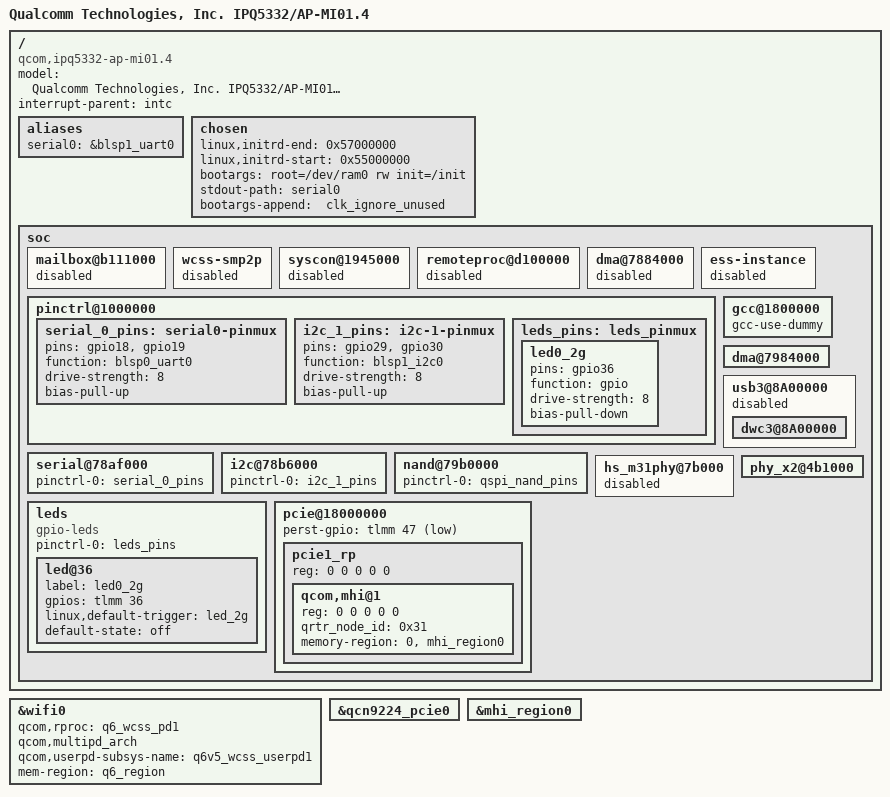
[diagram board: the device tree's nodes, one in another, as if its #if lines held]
// SPDX-License-Identifier: (GPL-2.0+ OR BSD-3-Clause)
/*
 * IPQ5332 AP-MI01.4 board device tree source
 *
 * Copyright (c) 2020-2021 The Linux Foundation. All rights reserved.
 * Copyright (c) 2022 Qualcomm Innovation Center, Inc. All rights reserved.
 */

/dts-v1/;

#include "ipq5332.dtsi"

#ifdef __IPQ_MEM_PROFILE_512_MB__
#include "ipq5332-512MB-memory.dtsi"
#else
#include "ipq5332-default-memory.dtsi"
#endif

/ {
	#address-cells = <0x2>;
	#size-cells = <0x2>;
	model = "Qualcomm Technologies, Inc. IPQ5332/AP-MI01.4";
	compatible = "qcom,ipq5332-ap-mi01.4", "qcom,ipq5332";
	interrupt-parent = <&intc>;

	aliases {
		serial0 = &blsp1_uart0;
	};

	chosen {
		linux,initrd-end = <0x57000000>;
		linux,initrd-start = <0x55000000>;
		bootargs = "root=/dev/ram0 rw init=/init";
		stdout-path = "serial0";
		bootargs-append = " clk_ignore_unused";
	};

	/*
	 * Below nodes are applicable for all RDPs, hence enabled by
	 * default in base dtsi file itself.
	 * So, rather than marking these nodes with status = "disabled",
	 * delete it. Once verified in silicon, we can remove the below
	 * snippet.
	 */

	/* Below nodes are QSEE dependent */
	/delete-node/ firmware;
	/delete-node/ qti,tzlog;
	/delete-node/ qti,scm_restart_reason;
	/delete-node/ ctx-save;
	/delete-node/ qseecom;

	/* Misc nodes */
	/delete-node/ pmu;
	/delete-node/ pmu-v7;
	/delete-node/ qti,gadget_diag@0;

	soc {

		/*
		 * Below nodes are applicable for all RDPs, hence enabled by
		 * default in base dtsi file itself.
		 * So, rather than marking these nodes with status = "disabled",
		 * delete it. Once verified in silicon, we can remove the below
		 * snippet.
		 */

		/* Misc nodes */
		/delete-node/ prng@e3000;
		/delete-node/ watchdog@b017000;
		/delete-node/ qcom,msm-imem@8600000;


		/delete-node/ syscon@193d100;
		/delete-node/ syscon@1905000;
		/delete-node/ hwlock;
		/delete-node/ smem;
		/delete-node/ scm;

		/*
		 * Below nodes are referenced by other nodes, deleting it
		 * will lead to build error, so disable it.
		 */
		mailbox@b111000 {
			status = "disabled";
		};
		wcss-smp2p {
			status = "disabled";
		};
		syscon@1945000 {
			status = "disabled";
		};
		remoteproc@d100000 {
			status = "disabled";
		};
		dma@7884000 {
			status = "disabled";
		};

		/* Not needed for the initial bringup */
		ess-instance {
			status = "disabled";
		};

		pinctrl@1000000 {
			serial_0_pins: serial0-pinmux {
				pins = "gpio18", "gpio19";
				function = "blsp0_uart0";
				drive-strength = <8>;
				bias-pull-up;
			};

			i2c_1_pins: i2c-1-pinmux {
				pins = "gpio29", "gpio30";
				function = "blsp1_i2c0";
				drive-strength = <8>;
				bias-pull-up;
			};

			leds_pins: leds_pinmux {
				led0_2g {
					pins = "gpio36";
					function = "gpio";
					drive-strength = <8>;
					bias-pull-down;
				};
			};
		};

		gcc@1800000 {
			gcc-use-dummy;
		};

		serial@78af000 {
			pinctrl-0 = <&serial_0_pins>;
			pinctrl-names = "default";
			status = "ok";
		};

		i2c@78b6000 {
			pinctrl-0 = <&i2c_1_pins>;
			pinctrl-names = "default";
		};

		dma@7984000 {
			status = "ok";
		};

		nand@79b0000 {
			pinctrl-0 = <&qspi_nand_pins>;
			pinctrl-names = "default";
			status = "ok";
		};

		usb3@8A00000 {
			status = "disabled";

			dwc3@8A00000 {
				/delete-property/ #phy-cells;
				/delete-property/ phys;
				/delete-property/ phy-names;
			};
		};

		hs_m31phy@7b000 {
			status = "disabled";
		};

		leds {
			compatible = "gpio-leds";
			pinctrl-0 = <&leds_pins>;
			pinctrl-names = "default";
			led@36 {
				label = "led0_2g";
				gpios = <&tlmm 36 GPIO_ACTIVE_HIGH>;
				linux,default-trigger = "led_2g";
				default-state = "off";
			};
		};

		phy_x2@4b1000 {
			status = "ok";
		};

		pcie@18000000 {
			perst-gpio = <&tlmm 47 GPIO_ACTIVE_LOW>;
			status = "ok";
			pcie1_rp {
				reg = <0 0 0 0 0>;

				qcom,mhi@1 {
					reg = <0 0 0 0 0>;
					qrtr_node_id = <0x31>;
					memory-region = <0>, <&mhi_region0>;
				};
			};
		};
	};
};

&wifi0 {
	qcom,rproc = <&q6_wcss_pd1>;
	qcom,multipd_arch;
	qcom,userpd-subsys-name = "q6v5_wcss_userpd1";
	mem-region = <&q6_region>;
	status = "ok";
};

&qcn9224_pcie0 {
	status = "ok";
};

&mhi_region0 {
	status = "ok";
};
